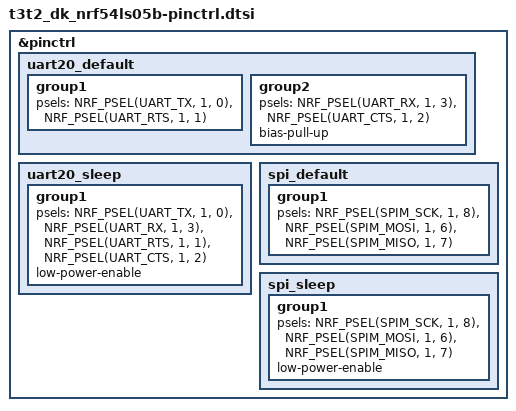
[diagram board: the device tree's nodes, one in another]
/*
 * Copyright (c) 2025 Trezor Company s.r.o.
 *
 * SPDX-License-Identifier: LicenseRef-Nordic-5-Clause
 */

&pinctrl {
	/*
	 * UART link to the STM32 main SoC (USART1 on the STM side).
	 * Pin/net mapping per schematic (PICO_MCU / Bluetooth Low Energy Radio):
	 *   nRF UART_TX  P1.00  -> net BLE_RX  (STM RX, PG10)
	 *   nRF UART_RX  P1.03  <- net BLE_TX  (STM TX, PB6)
	 *   nRF UART_RTS P1.01  -> net BLE_CTS (STM CTS, PG11)
	 *   nRF UART_CTS P1.02  <- net BLE_RTS (STM RTS, PG12)
	 */
	uart20_default: uart20_default {
		group1 {
			psels = <NRF_PSEL(UART_TX, 1, 0)>,
				<NRF_PSEL(UART_RTS, 1, 1)>;
		};
		group2 {
			psels = <NRF_PSEL(UART_RX, 1, 3)>,
				<NRF_PSEL(UART_CTS, 1, 2)>;
			bias-pull-up;
		};
	};

	uart20_sleep: uart20_sleep {
		group1 {
			psels = <NRF_PSEL(UART_TX, 1, 0)>,
				<NRF_PSEL(UART_RX, 1, 3)>,
				<NRF_PSEL(UART_RTS, 1, 1)>,
				<NRF_PSEL(UART_CTS, 1, 2)>;
			low-power-enable;
		};
	};

	/*
	 * SPI master to the STM32 main SoC (nRF is SPI master, STM is slave).
	 *   nRF SPIM_SCK  P1.08  -> net BLE_SCK  (STM PG2)
	 *   nRF SPIM_MOSI P1.06  -> net BLE_MOSI (STM PB5)
	 *   nRF SPIM_MISO P1.07  <- net BLE_MISO (STM PB4)
	 * CS (BLE_NSS, P1.05) is driven as a GPIO, see cs-gpios on &spi21.
	 */
	spi_default: spi_default {
		group1 {
			psels = <NRF_PSEL(SPIM_SCK, 1, 8)>,
				<NRF_PSEL(SPIM_MOSI, 1, 6)>,
				<NRF_PSEL(SPIM_MISO, 1, 7)>;
		};
	};

	spi_sleep: spi_sleep {
		group1 {
			psels = <NRF_PSEL(SPIM_SCK, 1, 8)>,
				<NRF_PSEL(SPIM_MOSI, 1, 6)>,
				<NRF_PSEL(SPIM_MISO, 1, 7)>;
			low-power-enable;
		};
	};
};
